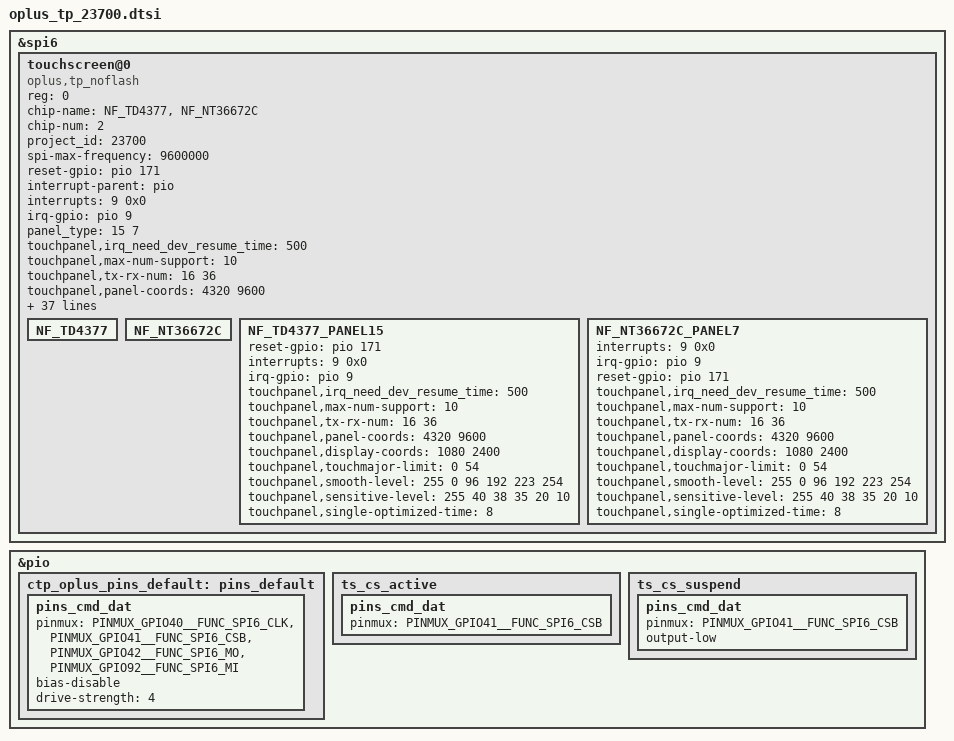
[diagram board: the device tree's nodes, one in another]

#include "mediatek/oplus-23700-tpfw.dtsi"
&spi6 {
	status = "okay";
	#address-cells = <1>;
	#size-cells = <0>;
	touchscreen@0 {
		compatible = "oplus,tp_noflash";
		reg = <0>;
		chip-name = "NF_TD4377","NF_NT36672C";
		status = "ok";
		chip-num = <2>;

		project_id = <23700>;
		spi-max-frequency = <9600000>;    /*4800000,9600000,15000000,19200000*/
		reset-gpio = <&pio 171 0x00>;
		interrupt-parent = <&pio>;
		interrupts = <9  0x0>;
		irq-gpio = <&pio 9 0x2002>;

		panel_type = <15 7>;  /*type:7 TIANMA type:15 HUAXING*/
		touchpanel,irq_need_dev_resume_time = <500>;
		touchpanel,max-num-support = <10>;
		touchpanel,tx-rx-num = <16 36>;			/*hd:18  32*/
		touchpanel,panel-coords = <4320 9600>;
		touchpanel,display-coords = <1080 2400>;	/*hd:720 1612*/
		touchpanel,touchmajor-limit = <0 54>;
		platform_support_project = <23615 23700 23701 23705>;
		platform_support_project_dir = <23700 23700 23700 23700>;
		platform_support_project_commandline = "oplus23700_csot_td4377_fhd_dsi_vdo_lcm_drv","oplus23700_tm_nt36672c_fhd_dsi_vdo_lcm_drv";		/* fhd*/
		firmware_name = "AB750HXTD01","AB750_TM_NT_01";
		pinctrl-names = "default", "pin_cs_high","pin_cs_low";
		pinctrl-0 = <&ctp_oplus_pins_default>;
		pinctrl-1 = <&ts_cs_active>;
		pinctrl-2 = <&ts_cs_suspend>;

		touchpanel,smooth-level = <255 0 96 192 223 254>;
		touchpanel,sensitive-level = <255 40 38 35 20 10>;
		touchpanel,single-optimized-time = <8>;

		incell_screen;
		irq_need_dev_resume_ok;
		fw_edge_limit_support;
		black_gesture_support;
		charger_pump_support;
		headset_pump_support;
		esd_handle_support;
		//spurious_fingerprint_support;
		//lcd_trigger_fp_check;
		black_gesture_test_support;
		noflash_support;
		smart_gesture_support;
		pressure_report_support;
		fw_update_app_support;
		game_switch_support;
		drlimit_remove_support;
		lcd_trigger_load_tp_fw_support;
		suspend_gesture_cfg;
		//fw_update_in_probe_with_headfile;
		health_monitor_support;
		//auto_test_force_pass_support;
		exception_upload_support;
		report_rate_white_list_support;
		touchpanel,button-type = <4>;
		palm_to_sleep_support;

		NF_TD4377 {

		};

		NF_NT36672C {

		};

		NF_TD4377_PANEL15 {
			reset-gpio = <&pio 171 0x00>;
			interrupts = <9  0x0>;
			irq-gpio = <&pio 9 0x2002>;

			touchpanel,irq_need_dev_resume_time = <500>;
			touchpanel,max-num-support = <10>;
			touchpanel,tx-rx-num = <16 36>;			/*hd:18  32*/
			touchpanel,panel-coords = <4320 9600>;
			touchpanel,display-coords = <1080 2400>;	/*hd:720 1612*/
			touchpanel,touchmajor-limit = <0 54>;
			touchpanel,smooth-level = <255 0 96 192 223 254>;
			touchpanel,sensitive-level = <255 40 38 35 20 10>;
			touchpanel,single-optimized-time = <8>;
		};

		NF_NT36672C_PANEL7 {
			interrupts = <9  0x0>;
			irq-gpio = <&pio 9 0x2002>;
			reset-gpio = <&pio 171 0x00>;

			touchpanel,irq_need_dev_resume_time = <500>;
			touchpanel,max-num-support = <10>;
			touchpanel,tx-rx-num = <16 36>;			/*hd:18  32*/
			touchpanel,panel-coords = <4320 9600>;
			touchpanel,display-coords = <1080 2400>;	/*hd:720 1612*/
			touchpanel,touchmajor-limit = <0 54>;
			touchpanel,smooth-level = <255 0 96 192 223 254>;
			touchpanel,sensitive-level = <255 40 38 35 20 10>;
			touchpanel,single-optimized-time = <8>;
		};
	};
};

&pio {
	ctp_oplus_pins_default: pins_default {
		pins_cmd_dat {
			pinmux = <PINMUX_GPIO40__FUNC_SPI6_CLK>,
					<PINMUX_GPIO41__FUNC_SPI6_CSB>,
					<PINMUX_GPIO42__FUNC_SPI6_MO>,
					<PINMUX_GPIO92__FUNC_SPI6_MI>;
			bias-disable;
			drive-strength = <4>;
		};
	};
	ts_cs_active: ts_cs_active {
		pins_cmd_dat {
			pinmux = <PINMUX_GPIO41__FUNC_SPI6_CSB>;
		};
	};
	ts_cs_suspend: ts_cs_suspend {
		pins_cmd_dat {
			pinmux = <PINMUX_GPIO41__FUNC_SPI6_CSB>;
			output-low;
		};
	};
};

